# ?: IP-XACT component
VLNV accellera.com:migration::1.0

## Address spaces and blocks
top_reg.SPI_TOP: base 0xFA12345678, range 3, width 32
top_reg.UART_TOP: base 0xEEEEAAAA, range 2, width 32

## Registers
Registers are 32-bit, access per field, reset 0x30F3F3 unless marked. A register's access mark holds for its fields unless they carry their own. Offsets are from the block's base; lines under a group give offsets from that group; [hi:lo] are bit positions; {n}, {i} and the like mark numbered series; 'fields as' and 'values as' point back to an identical list; <NAME> marks a mode.

## top_reg.SPI_TOP
Base 0xFA12345678
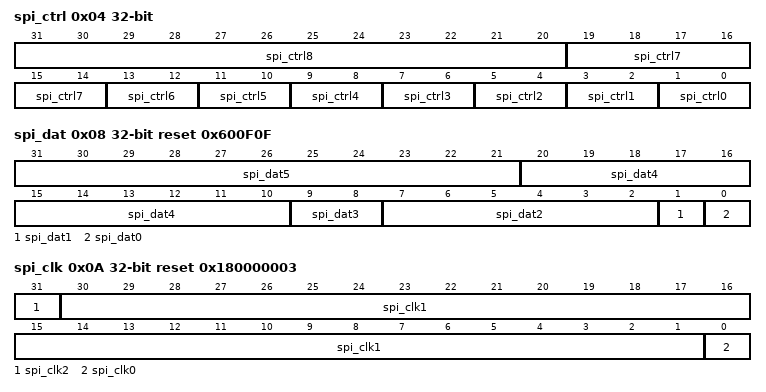
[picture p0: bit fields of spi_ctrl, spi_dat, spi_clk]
0x04 spi_ctrl
  [31:20] spi_ctrl8 ro, [19:14] spi_ctrl7 ro, [13:12] spi_ctrl6 ro, [11:10] spi_ctrl5 ro, [9:8] spi_ctrl4 rw, [7:6] spi_ctrl3 ro, [5:4] spi_ctrl2 ro, [3:2] spi_ctrl1 ro, [1:0] spi_ctrl0 rw
0x08 spi_dat reset 0x600F0F
  [31:21] spi_dat5 ro, [20:10] spi_dat4 rw, [9:8] spi_dat3 ro, [7:2] spi_dat2 ro, [1] spi_dat1 ro, [0] spi_dat0 rw
0x0A spi_clk reset 0x180000003
  [31] spi_clk2 ro, [30:1] spi_clk1 ro, [0] spi_clk0 rw

## top_reg.UART_TOP
Base 0xEEEEAAAA
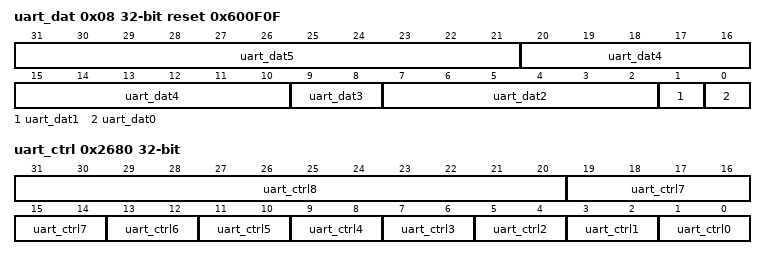
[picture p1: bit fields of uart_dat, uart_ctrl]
0x08 uart_dat reset 0x600F0F
  [31:21] uart_dat5 ro, [20:10] uart_dat4 rw, [9:8] uart_dat3 ro, [7:2] uart_dat2 ro, [1] uart_dat1 ro, [0] uart_dat0 rw
0x2680 uart_ctrl
  [31:20] uart_ctrl8 ro, [19:14] uart_ctrl7 ro, [13:12] uart_ctrl6 ro, [11:10] uart_ctrl5 ro, [9:8] uart_ctrl4 rw, [7:6] uart_ctrl3 ro, [5:4] uart_ctrl2 ro, [3:2] uart_ctrl1 ro, [1:0] uart_ctrl0 rw
